# GD32W515Px register map
File version: 1.0
CPU: CM33 r0p0, little endian, MPU, FPU, 4 interrupt priority bits
Registers are 32-bit, read-write, reset 0x0 unless marked. A register's access mark holds for its fields unless they carry their own. Offsets are from the block's base; [hi:lo] are bit positions.

## QSPI — Quad-SPI interface
Base 0x40025800
Same registers: SEC_QSPI 0x50025800
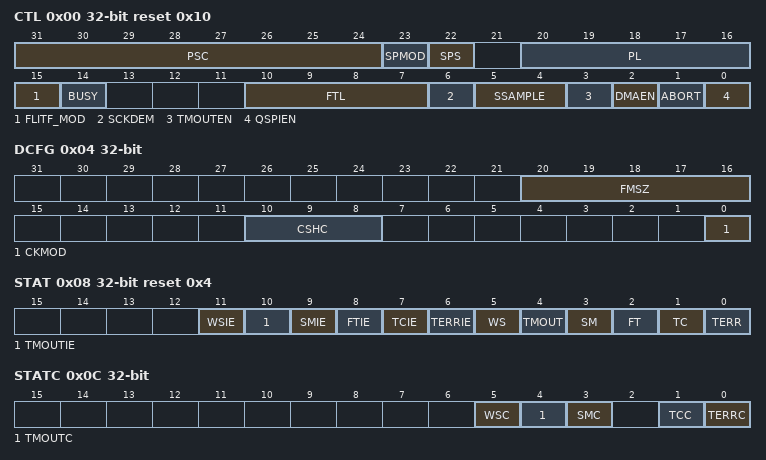
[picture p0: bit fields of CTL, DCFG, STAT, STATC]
0x00 CTL access per field reset 0x10 — control register
  [31:24] PSC rw — The scaler factor for generating SCK
  [23] SPMOD rw — Status Polling match mode
  [22] SPS rw — Status polling mode stop
  [20:16] PL rw — FIFO level
  [15] FLITF_MOD rw — Busy in FLITF mode
  [14] BUSY ro
  [10:7] FTL rw — FIFO threshold level
  [6] SCKDEM rw — SCK delay enable
  [5:4] SSAMPLE rw — Sample shift
  [3] TMOUTEN rw — Timeout counter enable
  [2] DMAEN rw — DMA enable
  [1] ABORT rw — Abort request
  [0] QSPIEN rw — QSPI enable
0x04 DCFG — Device configuration register
  [20:16] FMSZ — Flash memory size
  [10:8] CSHC — Chip select high cycle
  [0] CKMOD — the SCK level when QSPI is free
0x08 STAT access per field reset 0x4 — status register
  [11] WSIE rw — Wrong start sequence enable
  [10] TMOUTIE rw — Timeout enable
  [9] SMIE rw — Status match enable
  [8] FTIE rw — FIFO threshold enable
  [7] TCIE rw — Transfer complete interrupt enable
  [6] TERRIE rw — Transfer error interrupt enable
  [5] WS ro — Wrong start sequence flag
  [4] TMOUT ro — Timeout flag
  [3] SM ro — Status match flag
  [2] FT ro — FIFO threshold flag
  [1] TC ro — Transfer complete flag
  [0] TERR ro — Transfer error flag
0x0C STATC wo — Status clear register
  [5] WSC — Clear wrong start sequence flag
  [4] TMOUTC — Clear timeout flag
  [3] SMC — Clear status match flag
  [1] TCC — Clear timeout flag
  [0] TERRC — Clear transfer error flag
0x10 DTLEN — Data length register
  [31:0] DTLEN — Data length
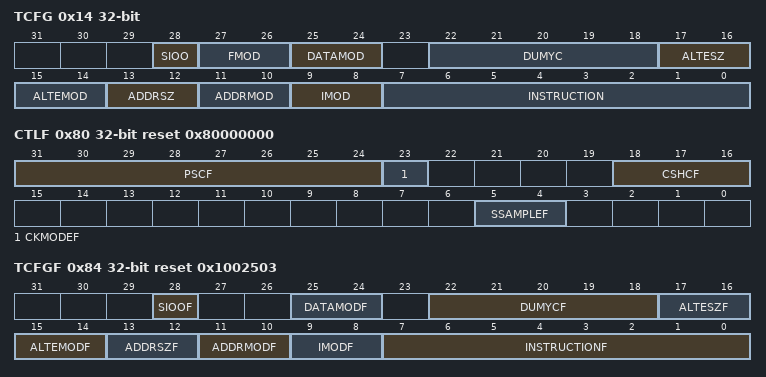
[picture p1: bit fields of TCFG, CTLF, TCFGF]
0x14 TCFG — Transfer configuration register
  [28] SIOO — Send instruction only once mode
  [27:26] FMOD — Functional mode
  [25:24] DATAMOD — Data mode
  [22:18] DUMYC — Number of dummy cycles
  [17:16] ALTESZ — Alternate bytes size
  [15:14] ALTEMOD — Alternate bytes mode
  [13:12] ADDRSZ — Address size
  [11:10] ADDRMOD — Address mode
  [9:8] IMOD — Instruction mode
  [7:0] INSTRUCTION
0x18 ADDR — Address register
  [31:0] ADDR — Address
0x1C ALTE — Alternate bytes register
  [31:0] ALTE — Alternate Bytes
0x20 DATA
0x24 STATMK — Status mask register
  [31:0] MASK — Status mask
0x28 STATMATCH — Status match register
  [31:0] MATCH — Status match
0x2C INTERVAL
  [31:0] INTERVAL — Interval cycle
0x30 TMOUT — Timeout register
  [15:0] TMOUT — Timeout cycle
0x34 FLUSH — FIFO flush register
  [0] FLUSH — Used to flush all qspi interal fifo
0x38 WTCNT reset 0x7A120 — Wait cnt for indirect wire mode register
  [31:0] WTCNT — Wait cnt when an indirect write operation is completed or aborted
0x3C SPTMOUT — Timeout for staus polling mode register
  [31:0] SPTMOUT — Timeout cnt when a flitf transfer trys to abort a staus polling mode opertaion
0x7C FLITF_SEC — FLITF mode security configuration register
  [0] SECURE_FLITF — Use for indicate if register of flitf mode
0x80 CTLF reset 0x80000000 — Control register in FLITF mode
  [31:24] PSCF — The scaler factor for generating SCK
  [23] CKMODEF — The SCK level in FLITF mode
  [18:16] CSHCF — Chip select high cycle in FLITF mode
  [5:4] SSAMPLEF — Sample shift in FLITF mode
0x84 TCFGF reset 0x1002503 — Transfer configuration register in FLITF mode
  [28] SIOOF — Send instruction only once mode in FLITF mode
  [25:24] DATAMODF — Data mode in FLITF mode
  [22:18] DUMYCF — Number of dummy cycles in FLITF mode
  [17:16] ALTESZF — Alternate bytes size in FLITF mode
  [15:14] ALTEMODF — Alternate bytes mode in FLITF mode
  [13:12] ADDRSZF — Address size in FLITF mode
  [11:10] ADDRMODF — Address mode in FLITF mode
  [9:8] IMODF — Instruction mode in FLITF mode
  [7:0] INSTRUCTIONF — Instruction in FLITF mode
0x88 ALTEF — Alternate bytes register in FLITF mode
  [31:0] ALTEF — Alternate Bytes in FLITF mode
0x8C BYTE_CNT — Complete bytes counter register
  [31:0] BYTECNT — Remained Bytes which has been aborted by FLITF mode
0x90 PRIV — Privilege configuration register
  [0] PRIV — Use for indicate if register is privileged
